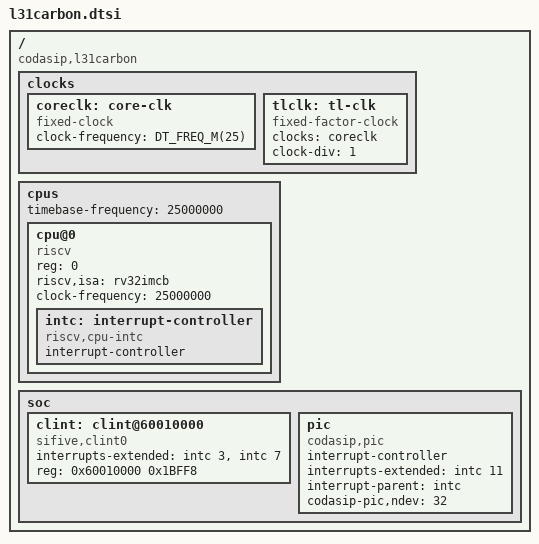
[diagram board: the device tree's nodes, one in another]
/* Copyright (c) 2023 Codasip s.r.o.   */
/* SPDX-License-Identifier: Apache-2.0 */

/* Info: dts/bindings/base/base.yaml */

#include "skeleton.dtsi"
#include <freq.h>
#include <mem.h>

/* Codasip Carbon L31 Core */

/ {
        compatible = "codasip,l31carbon";

        clocks {
                coreclk: core-clk {
                        #clock-cells = <0>;
                        compatible = "fixed-clock";
                        clock-frequency = <DT_FREQ_M(25)>;
                };

                tlclk: tl-clk {
                        #clock-cells = <0>;
                        compatible = "fixed-factor-clock";
                        clocks = <&coreclk>;
                        clock-div = <1>;
                };
        };

        cpus {
                #address-cells = <1>;
                #size-cells = <0>;
                timebase-frequency = <25000000>;
                cpu@0 {
                        compatible = "riscv";
                        device_type = "cpu";
                        reg = <0>;
                        riscv,isa = "rv32imcb";
                        clock-frequency = <25000000>;
                        status = "okay";
                        intc: interrupt-controller {
                                compatible = "riscv,cpu-intc";
                                #address-cells = <0>;
                                #interrupt-cells = <1>;
                                interrupt-controller;
                        };
                };
        };
        
        soc {
                clint: clint@60010000 {
                        compatible = "sifive,clint0";
                        interrupts-extended = <&intc 3>, <&intc 7>;
                        reg = <0x60010000 0x1BFF8>;
                };

                /* Carbon/Helium does not have a PLIC, only a Codasip PIC attached to CSR registers starting at 0x7C1.
                   The PIC just triggers the External Interrupt:
                      lib/include/baremetal/interrupt_low.h:    BM_INTERRUPT_MEIP = 11, // Machine external interrupt
                */
                pic: pic {
                        compatible = "codasip,pic";
                        interrupt-controller;
                        interrupts-extended = <&intc 11>;
                        #interrupt-cells = <1>;         /* Only interrupt bit positions (no priority on the PIC) */
                        interrupt-parent = <&intc>;
                        codasip-pic,ndev = <32>;    /* 32 Interrupts bits 31:0 */
                        status = "okay";
                };
        };
};
